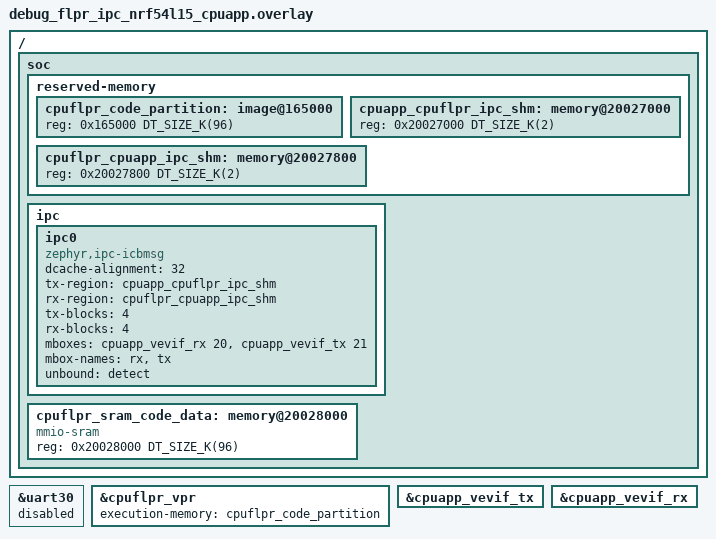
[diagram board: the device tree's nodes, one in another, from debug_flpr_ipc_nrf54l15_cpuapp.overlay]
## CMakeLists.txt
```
cmake_minimum_required(VERSION 3.20.0)
find_package(Zephyr REQUIRED HINTS $ENV{ZEPHYR_BASE})

project(debug_flpr_ipc)

# Collect all application sources under src (flat or nested) and add them to the app target.
file(GLOB_RECURSE app_sources src/*.c)
target_sources(app PRIVATE ${app_sources})

# Add the public include directory for headers in inc.
target_include_directories(app PRIVATE inc)
```

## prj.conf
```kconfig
CONFIG_USE_SEGGER_RTT=y
CONFIG_GNU_C_EXTENSIONS=y
CONFIG_DEBUG_OPTIMIZATIONS=y
CONFIG_CLOCK_CONTROL_NRF_K32SRC_RC=y
CONFIG_CONSOLE=y
CONFIG_RTT_CONSOLE=y
CONFIG_ASSERT=y

CONFIG_SEGGER_RTT_SECTION_CUSTOM_DTS_REGION=y
CONFIG_SEGGER_RTT_SECTION_CUSTOM_NAME="segger_rtt_data"

CONFIG_MBOX=y
CONFIG_IPC_SERVICE=y
CONFIG_IPC_SERVICE_ICMSG=y

CONFIG_LOG=y
CONFIG_LOG_DEFAULT_LEVEL=3
```

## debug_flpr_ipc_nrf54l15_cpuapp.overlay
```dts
/ {
	soc {
		reserved-memory {
			#address-cells = <1>;
			#size-cells = <1>;

			cpuflpr_code_partition: image@165000 {
				/* FLPR core code partition */
				reg = <0x165000 DT_SIZE_K(96)>;
			};

			/* Both cores must reserve the same two shared-memory ranges. */
			cpuapp_cpuflpr_ipc_shm: memory@20027000 {
				reg = <0x20027000 DT_SIZE_K(2)>;
			};

			cpuflpr_cpuapp_ipc_shm: memory@20027800 {
				reg = <0x20027800 DT_SIZE_K(2)>;
			};
		};

		ipc {
			ipc0: ipc0 {
				compatible = "zephyr,ipc-icbmsg";
				dcache-alignment = <32>;
				/* CPUAPP's TX is FLPR's RX, and CPUAPP's RX is FLPR's TX. */
				tx-region = <&cpuapp_cpuflpr_ipc_shm>;
				rx-region = <&cpuflpr_cpuapp_ipc_shm>;
				tx-blocks = <4>;
				rx-blocks = <4>;
				mboxes = <&cpuapp_vevif_rx 20>, <&cpuapp_vevif_tx 21>;
				mbox-names = "rx", "tx";
				unbound = "detect";
				status = "okay";
			};
		};

		cpuflpr_sram_code_data: memory@20028000 {
			compatible = "mmio-sram";
			reg = <0x20028000 DT_SIZE_K(96)>;
			#address-cells = <1>;
			#size-cells = <1>;
			ranges = <0x0 0x20028000 0x18000>;
		};
	};
};

&uart30 {
	status = "reserved";
};

&cpuflpr_vpr {
	execution-memory = <&cpuflpr_code_partition>;
};

&cpuapp_vevif_tx {
	status = "okay";
};

&cpuapp_vevif_rx {
	status = "okay";
};
```

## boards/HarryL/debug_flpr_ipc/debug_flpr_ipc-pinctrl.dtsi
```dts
&pinctrl {
	uart30_default: uart30_default {
		group1 {
			psels = <NRF_PSEL(UART_TX, 0, 0)>;
		};

		group2 {
			psels = <NRF_PSEL(UART_RX, 0, 1)>;
			bias-pull-up;
		};
	};

	uart30_sleep: uart30_sleep {
		group1 {
			psels = <NRF_PSEL(UART_TX, 0, 0)>,
				<NRF_PSEL(UART_RX, 0, 1)>;
			low-power-enable;
		};
	};

	spi21_default: spi21_default {
		group1 {
			psels = <NRF_PSEL(SPIM_SCK, 1, 4)>,
				<NRF_PSEL(SPIM_MOSI, 1, 0)>,
				<NRF_PSEL(SPIM_MISO, 1, 1)>,
				<NRF_PSEL(SPIM_CSN, 1, 3)>;
		};
	};

	spi21_sleep: spi21_sleep {
		group1 {
			psels = <NRF_PSEL(SPIM_SCK, 1, 4)>,
				<NRF_PSEL(SPIM_MOSI, 1, 0)>,
				<NRF_PSEL(SPIM_MISO, 1, 1)>,
				<NRF_PSEL(SPIM_CSN, 1, 3)>;
			low-power-enable;
		};
	};
};
```

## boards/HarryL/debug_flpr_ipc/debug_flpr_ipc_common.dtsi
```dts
#include "debug_flpr_ipc-pinctrl.dtsi"

&uart30 {
	current-speed = <115200>;
	pinctrl-0 = <&uart30_default>;
	pinctrl-1 = <&uart30_sleep>;
	pinctrl-names = "default", "sleep";
	status = "disabled";
};
```

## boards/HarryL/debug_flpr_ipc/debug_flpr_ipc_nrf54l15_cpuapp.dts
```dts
/dts-v1/;
#include <nordic/nrf54l15_cpuapp.dtsi>
#include "debug_flpr_ipc_common.dtsi"

/ {
	model = "debug_flpr_ipc";
	compatible = "HarryL,debug-flpr-ipc-cpuapp";

	chosen {
		zephyr,code-partition = &slot0_partition;
		zephyr,sram = &cpuapp_sram;
		zephyr,flash = &cpuapp_rram;
		zephyr,flash-controller = &rram_controller;
	};

	clocks {
		lfxo: lfxo {
			status = "disabled";
		};
	};

	aliases {
		rtt-custom-section = &rtt_ram_region;
	};
};

&cpuapp_sram {
	reg = <0x20000000 0x26000>;
	ranges = <0x0 0x20000000 0x26000>;

	rtt_ram_region: memory@25000 {
		compatible = "zephyr,memory-region", "mmio-sram";
		reg = <0x25000 DT_SIZE_K(4)>;
		zephyr,memory-region = "segger_rtt_data";
	};
};

&cpuapp_rram {
	partitions {
		compatible = "fixed-partitions";
		#address-cells = <1>;
		#size-cells = <1>;

		slot0_partition: partition@0 {
			label = "image-0";
			reg = <0 DT_SIZE_K(664)>;
		};
	};
};

&grtc {
	owned-channels = <0 1 2 3 4 5 6 7 8 9 10 11>;
	/* Channels 7-11 reserved for Zero Latency IRQs, 3-4 for FLPR */
	child-owned-channels = <3 4 7 8 9 10 11>;
	status = "okay";
};

&uicr {
	nfct-pins-as-gpios;
};

&cpuflpr_vpr {
	status = "okay";
};
```

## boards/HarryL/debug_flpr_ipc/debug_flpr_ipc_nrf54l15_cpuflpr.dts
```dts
/dts-v1/;
#include <nordic/nrf54l15_cpuflpr.dtsi>
#include "debug_flpr_ipc_common.dtsi"

/delete-node/ &cpuflpr_sram;

/ {
	model = "debug_flpr_ipc";
	compatible = "HarryL,debug-flpr-ipc-cpuflpr";

	chosen {
		zephyr,code-partition = &cpuflpr_code_partition;
		zephyr,flash = &cpuflpr_rram;
		zephyr,sram = &cpuflpr_sram;
	};

	cpuflpr_sram: memory@20028000 {
		compatible = "mmio-sram";
		/* Size must be increased due to booting from SRAM */
		reg = <0x20028000 DT_SIZE_K(96)>;
		#address-cells = <1>;
		#size-cells = <1>;
		ranges = <0x0 0x20028000 0x18000>;
		status = "okay";
	};
};

&cpuflpr_rram {
	partitions {
		#address-cells = <1>;
		#size-cells = <1>;
		ranges;
		cpuflpr_code_partition: partition@0 {
			label = "image-0";
			compatible = "zephyr,mapped-partition";
			reg = <0 DT_SIZE_K(96)>;
		};
	};
};

&grtc {
	owned-channels = <3 4>;
	status = "okay";
};

&gpiote20 {
	fixed-channels-supported;
	owned-channels = <7>;
	status = "okay";
};

&gpiote30 {
	status = "okay";
};

&gpio2 {
	status = "okay";
};

&gpio1 {
	status = "okay";
};

&gpio0 {
	status = "okay";
};

&uart30 {
	status = "disabled";
};
```

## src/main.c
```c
#include <stdio.h>
#include <string.h>
#include <stdbool.h>
#include <stdint.h>
#include "SEGGER_RTT.h"
#include <zephyr/logging/log.h>

#include <zephyr/kernel.h>
#include <zephyr/device.h>
#include <zephyr/logging/log.h>

#include "ipc.h"

LOG_MODULE_REGISTER(main, LOG_LEVEL_INF);

int main(void)
{
    /* Register the receiver that prints FLPR logs through CPUAPP's RTT console. */
    dbgmsg_ipc_init();
    while (1)
    {
        LOG_INF("Hello from ARM");
        k_sleep(K_MSEC(1000));
    }
    return 0;
}
```

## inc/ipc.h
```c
#ifndef __ipc_h
#define __ipc_h
#include <zephyr/types.h>

/* Register CPUAPP's debug-log receiver; initialization errors are logged. */
void dbgmsg_ipc_init(void);
void magdata_ipc_init(void);
int magdata_ipc_send(const void *data, size_t len);

#endif /* __ipc_h */
```

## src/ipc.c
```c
#include "ipc.h"

#include <zephyr/ipc/ipc_service.h>
#include <zephyr/logging/log.h>
LOG_MODULE_REGISTER(cpu_ipc, CONFIG_LOG_DEFAULT_LEVEL);

/* Debug message IPC */
static void dbgmsg_bound(void *priv)
{
    // k_sem_give(&bound_sem);
    LOG_INF("dbgmsg ep bounded");
}
static void dbgmsg_unbound(void *priv)
{
    LOG_INF("dbgmsg ep unbounded");
}
static void dbgmsg_recv(const void *data, size_t len, void *priv)
{
    /* IPC text need not be NUL-terminated; bound output by the received length. */
    printk("FLPR DBG:%.*s", (int)len, (const char *)data);
}
static void ep_error(const char *err, void *priv)
{
    LOG_ERR("ep error %s", err);
}

static struct ipc_ept_cfg dbgmsg_ep_cfg = {
    .cb = {
        .bound = dbgmsg_bound,
        .unbound = dbgmsg_unbound,
        .received = dbgmsg_recv,
        .error = ep_error,
    },
    /* This name must match the endpoint registered by FLPR. */
    .name = "dbgmsg_ep",
};

static struct ipc_ept dbgmsg_ep;
static const struct device *dbgmsg_ipc_dev;

void dbgmsg_ipc_init(void)
{
    int ret;

    dbgmsg_ipc_dev = DEVICE_DT_GET(DT_NODELABEL(ipc0));
    ret = ipc_service_open_instance(dbgmsg_ipc_dev);
    /* An already-open IPC instance can still be used to register this endpoint. */
    if ((ret < 0) && (ret != -EALREADY))
    {
        LOG_ERR("ipc_service_open_instance() failure");
    }
    /* Registration starts the handshake; dbgmsg_bound() reports readiness. */
    ret = ipc_service_register_endpoint(dbgmsg_ipc_dev, &dbgmsg_ep, &dbgmsg_ep_cfg);
    if (ret < 0)
    {
        LOG_ERR("ipc_service_register_endpoint() failure");
    }
}
```
